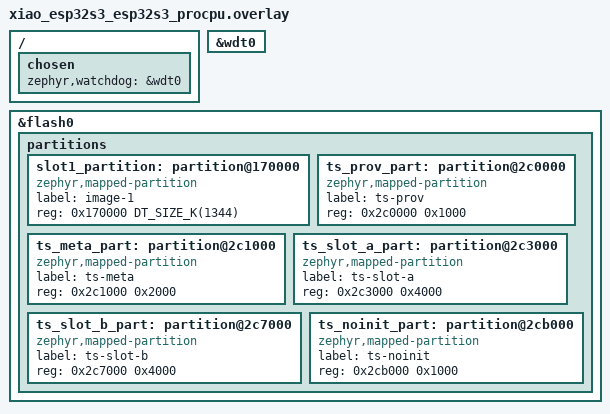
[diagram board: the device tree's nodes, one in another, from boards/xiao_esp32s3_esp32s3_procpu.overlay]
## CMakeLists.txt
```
# SPDX-License-Identifier: Apache-2.0
cmake_minimum_required(VERSION 3.20.0)
find_package(Zephyr REQUIRED HINTS $ENV{ZEPHYR_BASE})
project(otabench)

# WiFi 凭证经环境变量注入（sysbuild 不转发任意 cmake 变量到子镜像——
# ENV{} 直读可靠；仓库不含凭证，军规）。
target_compile_definitions(app PRIVATE
  OTAB_WIFI_SSID="$ENV{OTAB_WIFI_SSID}"
  OTAB_WIFI_PASSWORD="$ENV{OTAB_WIFI_PASSWORD}")

target_sources(app PRIVATE src/main.c)
```

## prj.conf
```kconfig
# SPDX-License-Identifier: Apache-2.0
# otabench（单元 G2）：MCUmgr OTA——MCUboot（sysbuild 子镜像）+ SMP 串口
# （DEC-23 UART 救砖底线）。UDP 传输受 WSL mirrored Hyper-V 防火墙面阻挡
# （owner UAC 手动步骤，登记）——串口线协议不受此面影响。

# 框架最小面（无 zenoh/无 APP/无 store——OTA 证据 = 固件版本链）
CONFIG_TS_CORE=y
CONFIG_TS_SAFETY=y
CONFIG_TS_NET=n
CONFIG_TS_APPMGR=n
CONFIG_TS_APP_WAMR=n
CONFIG_TS_STORE=n
CONFIG_TS_PERIPH=n
CONFIG_TS_POWER=n
CONFIG_TS_HAL=n
CONFIG_FLASH=y
CONFIG_FLASH_MAP=y
CONFIG_REBOOT=y
CONFIG_MAIN_STACK_SIZE=8192
CONFIG_MAIN_THREAD_PRIORITY=15

# 网络：WiFi STA + DHCPv4（netbench 同档；保留网络面供遥测/alive）
CONFIG_NETWORKING=y
CONFIG_NET_L2_ETHERNET=y
CONFIG_NET_IPV4=y
CONFIG_NET_ARP=y
CONFIG_NET_UDP=y
CONFIG_NET_TCP=y
CONFIG_NET_SOCKETS=y
CONFIG_NET_DHCPV4=y
CONFIG_WIFI=y
CONFIG_NET_MAX_CONTEXTS=12
CONFIG_HEAP_MEM_POOL_SIZE=98304
CONFIG_ENTROPY_GENERATOR=y

# MCUmgr：SMP over UDP（WiFi）—— 串口 shell 传输不可用（USB serial JTAG
# 控制台无 UART_CONSOLE_MCUMGR 透传 = esp32s3 平台限制，如实登记）
CONFIG_NET_BUF=y
CONFIG_ZCBOR=y
CONFIG_CRC=y
CONFIG_MCUMGR=y
CONFIG_MCUMGR_TRANSPORT_UDP=y
CONFIG_MCUMGR_TRANSPORT_UDP_IPV4=y
CONFIG_MCUMGR_TRANSPORT_UDP_AUTOMATIC_INIT=y
CONFIG_MCUMGR_GRP_IMG=y
CONFIG_MCUMGR_GRP_OS=y
CONFIG_IMG_MANAGER=y
CONFIG_STREAM_FLASH=y
CONFIG_MCUMGR_TRANSPORT_NETBUF_SIZE=512
CONFIG_SYSTEM_WORKQUEUE_STACK_SIZE=2304

# 看门狗（DEC-48 常设）
CONFIG_WATCHDOG=y
CONFIG_TASK_WDT_HW_FALLBACK=y
CONFIG_TASK_WDT_MIN_TIMEOUT=5000
CONFIG_TASK_WDT_HW_FALLBACK_DELAY=5000

# 日志（SMP 调试期）
CONFIG_LOG=y
```

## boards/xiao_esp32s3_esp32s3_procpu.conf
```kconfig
# otabench 板级内存（无 zenoh → 中档堆）
CONFIG_ESP_SPIRAM=y
CONFIG_SPIRAM_MODE_OCT=y
CONFIG_ESP_SPIRAM_MEMTEST=y
CONFIG_HEAP_MEM_POOL_SIZE=98304
# 4.5 复验批（同型防御）：verify 链在 4096 main 栈实测挂死（persistbench
# 实证——教训 31⑤ 同型）；8192 定值。
CONFIG_MAIN_STACK_SIZE=8192
```

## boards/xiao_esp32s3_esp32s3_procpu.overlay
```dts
/*
 * otabench（单元 G2；v4.5 适配批修订）：MCUboot OTA 分区——image-1 为完整
 * OTA 槽（AMP 4M 原位 0x170000），ts 五分区后移 0x2C0000（8MB 空闲区）。
 * mcuboot@0x0(64K) / sys@0x10000(64K) / image-0@0x20000(1344K) /
 * image-1@0x170000(1344K) / ts-{prov,meta,slot-a,slot-b,noinit}@0x2C0000。
 * v4.5：分区节点须带 compatible = "zephyr,mapped-partition"；默认布局新增
 * appcpu/lpcore 分区（0x2C0000 起）与 ts 五分区重叠——删除之。
 */

&wdt0 {
	status = "okay";
};

/ {
	chosen {
		zephyr,watchdog = &wdt0;
	};
};

/delete-node/ &slot0_appcpu_partition;
/delete-node/ &slot1_appcpu_partition;
/delete-node/ &slot0_lpcore_partition;
/delete-node/ &slot1_lpcore_partition;

&flash0 {
	partitions {
		slot1_partition: partition@170000 {
			compatible = "zephyr,mapped-partition";
			label = "image-1";
			reg = <0x170000 DT_SIZE_K(1344)>;
		};
		ts_prov_part: partition@2c0000 {
			compatible = "zephyr,mapped-partition";
			label = "ts-prov";
			reg = <0x2c0000 0x1000>;
		};
		ts_meta_part: partition@2c1000 {
			compatible = "zephyr,mapped-partition";
			label = "ts-meta";
			reg = <0x2c1000 0x2000>;
		};
		ts_slot_a_part: partition@2c3000 {
			compatible = "zephyr,mapped-partition";
			label = "ts-slot-a";
			reg = <0x2c3000 0x4000>;
		};
		ts_slot_b_part: partition@2c7000 {
			compatible = "zephyr,mapped-partition";
			label = "ts-slot-b";
			reg = <0x2c7000 0x4000>;
		};
		ts_noinit_part: partition@2cb000 {
			compatible = "zephyr,mapped-partition";
			label = "ts-noinit";
			reg = <0x2cb000 0x1000>;
		};
	};
};
```

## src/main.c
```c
/* SPDX-License-Identifier: Apache-2.0 */
/* otabench（单元 G2）：MCUmgr 固件 OTA 真机载体——MCUboot（sysbuild）+
 * SMP over UDP（WiFi）+ 真机 OTA 全链（v1 运行 → upload v2 → confirm →
 * reset → v2 运行）。
 * 判据（OTA* console 行 + PC 客户端 image list 双证据）：
 *   OTA0 版本自报（v1）；OTA1 WiFi IP；OTA2 SMP 服务在位
 *   （PC 侧：upload → image list 显 slot1=v2 → confirm → reset → 复位后
 *    OTA0 版本自报（v2）+ image list 显 running v2）
 * 无 zenoh（SMP 即本载体的传输面）；无 APP（OTA 证据 = 固件版本）。 */
#include <string.h>
#include <zephyr/net/net_event.h>
#include <zephyr/net/net_if.h>
#include <zephyr/net/net_mgmt.h>
#include <zephyr/net/wifi_mgmt.h>
#include <zephyr/net/dhcpv4.h>
#include <zephyr/kernel.h>
#include <zephyr/sys/printk.h>
#include <zephyr/sys/reboot.h>
#include <ts/core.h>
#include <ts/safety.h>
#include <ts/store.h>

/* WiFi 凭证经 cmake CACHE 变量注入（本地脚本，不入仓库） */
#ifndef OTAB_WIFI_SSID
#define OTAB_WIFI_SSID ""
#endif
#ifndef OTAB_WIFI_PASSWORD
#define OTAB_WIFI_PASSWORD ""
#endif

/* WiFi glue（netbench 板级七定稿模式——deploybench 同语义） */
static struct net_mgmt_event_callback ip_cb;
static struct net_mgmt_event_callback wifi_cb;
static atomic_t assoc_ok_evt;
static atomic_t disconn_evt;
static struct k_work_delayable wifi_retry_work;
static struct k_work assoc_work;
static struct wifi_connect_req_params cnx;
static struct k_sem ip_ready;

static void wifi_try_connect(struct k_work *w)
{
	ARG_UNUSED(w);
	int rc = net_mgmt(NET_REQUEST_WIFI_CONNECT, net_if_get_default(),
			  &cnx, sizeof(cnx));

	if (rc != 0) {
		k_work_reschedule(&wifi_retry_work, K_SECONDS(2));
	}
}

static void wifi_assoc_work(struct k_work *w)
{
	ARG_UNUSED(w);
	struct net_if *iface = net_if_get_default();

	if (atomic_set(&disconn_evt, 0) == 1) {
		net_dhcpv4_restart(iface);
		k_work_reschedule(&wifi_retry_work, K_SECONDS(2));
	}
	if (atomic_set(&assoc_ok_evt, 0) == 1) {
		struct wifi_ps_params ps = {.enabled = WIFI_PS_DISABLED};

		(void)net_mgmt(NET_REQUEST_WIFI_PS, iface, &ps, sizeof(ps));
		printk("OTAw associated t=%u\n", (unsigned)k_uptime_get_32());
	}
}

static void ip_handler(struct net_mgmt_event_callback *cb, uint64_t event,
		       struct net_if *iface)
{
	ARG_UNUSED(cb);
	if (event == NET_EVENT_IPV4_ADDR_ADD && net_if_is_up(iface)) {
		k_sem_give(&ip_ready);
	}
}

static void wifi_handler(struct net_mgmt_event_callback *cb, uint64_t event,
			 struct net_if *iface)
{
	ARG_UNUSED(iface);
	if (event == NET_EVENT_WIFI_CONNECT_RESULT) {
		const struct wifi_status *st = (const struct wifi_status *)cb->info;

		if (st != NULL && st->status == 0) {
			atomic_set(&assoc_ok_evt, 1);
		}
	} else if (event == NET_EVENT_WIFI_DISCONNECT_RESULT) {
		atomic_set(&disconn_evt, 1);
	}
	if (atomic_get(&assoc_ok_evt) == 1 || atomic_get(&disconn_evt) == 1) {
		k_work_submit(&assoc_work);
	}
}

/* prov：本地 OTA 载体缺省 ids（dev 缺省——本载体验证面 = 固件版本链） */
static void ota_alive(struct k_work *w)
{
	struct k_work_delayable *d = k_work_delayable_from_work(w);

	printk("OTA3 alive t=%u img-ver=%s\n", (unsigned)k_uptime_get_32(),
	       CONFIG_MCUBOOT_IMGTOOL_SIGN_VERSION);
	k_work_reschedule_for_queue(&k_sys_work_q, d, K_SECONDS(10));
}
static struct k_work_delayable ota_alive_work;

int main(void)
{
	printk("OTA0 otabench（单元 G2：MCUmgr OTA）img-ver=%s\n",
	       CONFIG_MCUBOOT_IMGTOOL_SIGN_VERSION);

	struct net_if *iface = net_if_get_default();

	k_sem_init(&ip_ready, 0, 1);
	k_work_init_delayable(&wifi_retry_work, wifi_try_connect);
	k_work_init(&assoc_work, wifi_assoc_work);
	net_mgmt_init_event_callback(&ip_cb, ip_handler, NET_EVENT_IPV4_ADDR_ADD);
	net_mgmt_add_event_callback(&ip_cb);
	net_mgmt_init_event_callback(&wifi_cb, wifi_handler,
				     NET_EVENT_WIFI_CONNECT_RESULT |
				     NET_EVENT_WIFI_DISCONNECT_RESULT);
	net_mgmt_add_event_callback(&wifi_cb);

	static const uint8_t ssid[] = OTAB_WIFI_SSID;
	static const uint8_t psk[] = OTAB_WIFI_PASSWORD;

	cnx = (struct wifi_connect_req_params){
		.ssid = ssid,
		.ssid_length = sizeof(ssid) - 1,
		.psk = psk,
		.psk_length = sizeof(psk) - 1,
		.security = WIFI_SECURITY_TYPE_PSK,
		.channel = WIFI_CHANNEL_ANY,
		.band = WIFI_FREQ_BAND_2_4_GHZ,
		.mfp = WIFI_MFP_OPTIONAL,
	};

	int rc = net_mgmt(NET_REQUEST_WIFI_CONNECT, iface, &cnx, sizeof(cnx));

	printk("OTA1 wifi_connect rc=%d\n", rc);
	if (k_sem_take(&ip_ready, K_SECONDS(40)) != 0) {
		printk("OTA FAIL dhcp timeout\n");
		return 1;
	}
	/* IPv4 地址自报（SMP UDP 客户端目标） */
	char buf[NET_IPV4_ADDR_LEN];

	if (net_addr_ntop(AF_INET,
			  &iface->config.ip.ipv4->unicast[0].ipv4.address.in_addr,
			  buf, sizeof(buf)) != NULL) {
		printk("OTA2 ip=%s smp-udp :1337\n", buf);
	}
	/* G2 收口修正（B2 后续）：smp_udp 在 SYS_INIT 早期（WiFi 关联前）
	 * 已启动——esp32 上 pre-IP 绑定的 UDP 套接字收不到后续到达的单播
	 * （线上铁证：请求出线 + ARP 通 + 板零回包）。拿到地址后重启
	 * smp_udp（close+open 重建套接字），绑定语义随 iface 就位。 */
	{
		extern int smp_udp_close(void);
		extern int smp_udp_open(void);
		int c = smp_udp_close();
		int o = smp_udp_open();

		printk("OTA2b smp_udp restart close=%d open=%d\n", c, o);
	}
	k_work_init_delayable(&ota_alive_work, ota_alive);
	k_work_reschedule_for_queue(&k_sys_work_q, &ota_alive_work, K_SECONDS(10));

	ts_core_boot(); /* noreturn：框架 boot 序（estop/poweron/wdt/core） */
	return 0;
}
```
